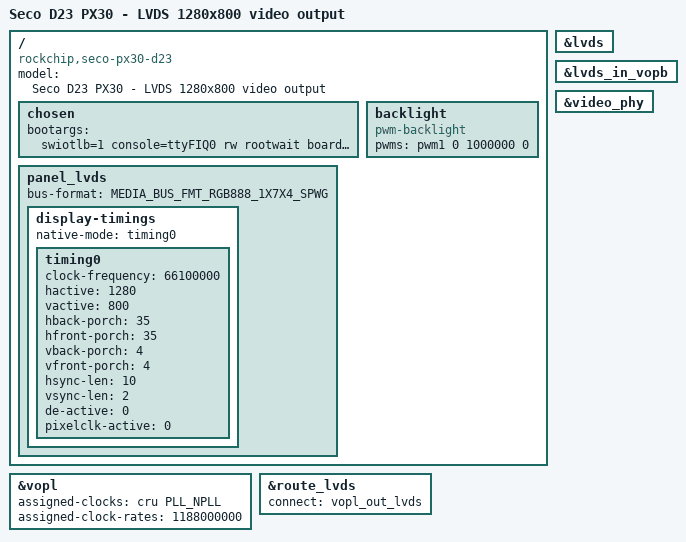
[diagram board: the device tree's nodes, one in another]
/*
 * Copyright 2020 SECO
 *
 * This program is free software; you can redistribute it and/or
 * modify it under the terms of the GNU General Public License
 * as published by the Free Software Foundation; either version 2
 * of the License, or (at your option) any later version.
 *
 * This program is distributed in the hope that it will be useful,
 * but WITHOUT ANY WARRANTY; without even the implied warranty of
 * MERCHANTABILITY or FITNESS FOR A PARTICULAR PURPOSE.  See the
 * GNU General Public License for more details.
 */

/dts-v1/;
/plugin/;

#include <dt-bindings/clock/px30-cru.h>
#include <dt-bindings/display/media-bus-format.h>

/ {
	model = "Seco D23 PX30 - LVDS 1280x800 video output";
	compatible = "rockchip,seco-px30-d23", "rockchip,px30", "rockchip,linux", "rockchip,rk3326";

/*  __________________________________________________________________________
 * |                                                                          |
 * |                                LVDS		                        |
 * |__________________________________________________________________________|
 */

	fragment@0 {
		target-path = "/";
		__overlay__ {
			chosen {
				bootargs = "swiotlb=1 console=ttyFIQ0 rw rootwait board_revC-LVDS1280";
			};

			backlight: backlight {
				compatible = "pwm-backlight";
				pwms = <&pwm1 0 1000000 0>;
			};

			panel_lvds {
				bus-format = <MEDIA_BUS_FMT_RGB888_1X7X4_SPWG>;
				display-timings {
					native-mode = <&timing0>;

					timing0: timing0 {
						clock-frequency = <66100000>;
						hactive = <1280>;
						vactive = <800>;
						hback-porch = <35>;
						hfront-porch = <35>;
						vback-porch = <4>;
						vfront-porch = <4>;
						hsync-len = <10>;
						vsync-len = <2>;
						de-active = <0>;
						pixelclk-active = <0>;
					};
				};
			};
		};
	};

	fragment@1 {
		target = <&lvds>;
		__overlay__ {
			status = "okay";
		};
	};

	fragment@2 {
		target = <&lvds_in_vopb>;
		__overlay__ {
			status = "okay";
		};
	};

	fragment@3 {
		target = <&vopl>;
		__overlay__ {
			status = "okay";
			assigned-clocks = <&cru PLL_NPLL>;
			assigned-clock-rates = <1188000000>;
		};
	};

	fragment@4 {
		target = <&video_phy>;
		__overlay__ {
			status = "okay";
		};
	};

	fragment@5 {
		target = <&route_lvds>;
		__overlay__ {
			connect = <&vopl_out_lvds>;
			status = "okay";
		};
	};
};
